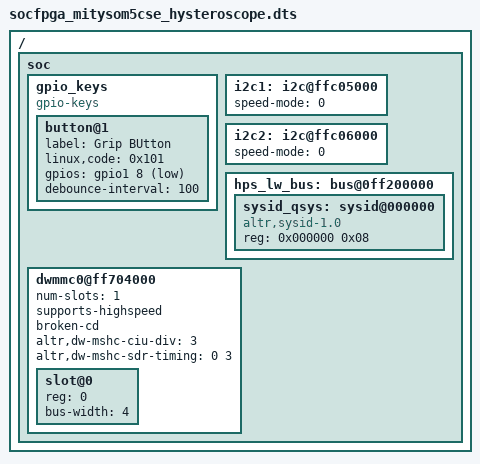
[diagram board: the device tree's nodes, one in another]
#include "socfpga_mitysom5cse.dtsi"
#include <dt-bindings/interrupt-controller/irq.h>

/ {
	soc {

		/* TODO -- change to use correct GPIO for grip button */
		gpio_keys {
			compatible = "gpio-keys";
			#address-cells = <1>;
			#size-cells = <0>;
			/* GPIO 37 */
			button@1 {
				label = "Grip BUtton";
				linux,code = <0x101>;
				gpios = <&gpio1 8 1>;
				debounce-interval = <100>;
			};
		};

		/* used for HDMI interface */
		i2c1: i2c@ffc05000 {
			speed-mode = <0>;
			status = "okay";
		};

		i2c2: i2c@ffc06000 {
			speed-mode = <0>;
			status = "okay";
		};

		hps_lw_bus: bus@0ff200000 {
			status = "okay";

			sysid_qsys: sysid@000000 {
				compatible = "altr,sysid-1.0";
				reg = <0x000000 0x08>;
			};
		};

		dwmmc0@ff704000 {
			num-slots = <1>;
			supports-highspeed;
			broken-cd;
			altr,dw-mshc-ciu-div = <3>;
			altr,dw-mshc-sdr-timing = <0 3>;

			slot@0 {
				reg = <0>;
				bus-width = <4>;
			};
		};
	};
};
